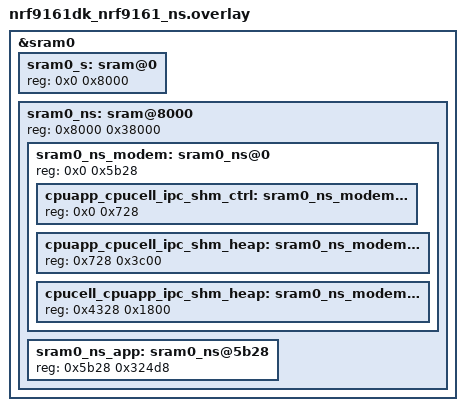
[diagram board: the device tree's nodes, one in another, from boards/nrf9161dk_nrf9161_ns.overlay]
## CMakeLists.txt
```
#
# Copyright (c) 2024 Nordic Semiconductor
#
# SPDX-License-Identifier: LicenseRef-Nordic-5-Clause
#

cmake_minimum_required(VERSION 3.20.0)

find_package(Zephyr REQUIRED HINTS $ENV{ZEPHYR_BASE})
project(hello_dect)

target_sources(app PRIVATE src/main.c)
```

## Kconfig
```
#
# Copyright (c) 2024 Nordic Semiconductor
#
# SPDX-License-Identifier: LicenseRef-Nordic-5-Clause
#

config CARRIER
	int "Carrier to use"
	default 0
	help
	   The availability of the channels and the exact regulation to use them varies in different countries.
	   See ETSI TS 103 636-2 5.4.2 for the calculation.
	   Band index 1 is set when the carrier is within the range of 525 to 551.
	   This is the only range allowed for band index 1 as other carriers will interfere with other radio devices, including LTE devices.

config NETWORK_ID
	int "Network ID"
	range 1 4294967295
	default 91

config MCS
	int "MCS"
	default 1
	help
	   The MCS impacts how much data can fit into each subslot.

config TX_POWER
	int "TX power"
	range 0 13
	default 13
	help
	   Transmission power, max 19 dBm due to hardware limitations.
	   See table 6.2.1-3 of ETSI TS 103 636-4 v1.5.1.

config TX_TRANSMISSIONS
	int "TX transmissions"
	range 0 4294967295
	default 30
	help
	   Transmissions before sample exits, use 0 to transmit forever.

config RX_PERIOD_S
	int "RX period"
	default 5
	help
	   Receive window period.
	   Time is given in seconds.

module = DECT_PHY_HELLO
module-str = DECT NR+ PHY Hello
source "$(ZEPHYR_BASE)/subsys/logging/Kconfig.template.log_config"

menu "Zephyr Kernel"
source "Kconfig.zephyr"
endmenu
```

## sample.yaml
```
sample:
  name: Dect NR+ PHY Hello
tests:
  sample.dect_phy.dect_hello.eu.sysbuild:
    sysbuild: true
    build_only: true
    integration_platforms:
      - nrf9151dk/nrf9151/ns
    platform_allow:
      - nrf9151dk/nrf9151/ns
    extra_args: EXTRA_CONF_FILE="overlay-eu.conf"
    tags:
      - ci_build
      - sysbuild
      - ci_samples_dect
  sample.dect_phy.dect_hello.us.sysbuild:
    sysbuild: true
    build_only: true
    integration_platforms:
      - nrf9151dk/nrf9151/ns
    platform_allow:
      - nrf9151dk/nrf9151/ns
    extra_args: EXTRA_CONF_FILE="overlay-us.conf"
    tags:
      - ci_build
      - sysbuild
      - ci_samples_dect
```

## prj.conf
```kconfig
CONFIG_TFM_PROFILE_TYPE_MINIMAL=y

CONFIG_NRF_MODEM_LIB=y

CONFIG_MODEM_ANTENNA=n

CONFIG_NRF_MODEM_LINK_BINARY_DECT_PHY=y
CONFIG_HWINFO=y

CONFIG_LOG=y
```

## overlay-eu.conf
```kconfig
CONFIG_CARRIER=1677
```

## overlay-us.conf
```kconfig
CONFIG_CARRIER=1711
CONFIG_TX_POWER=10
```

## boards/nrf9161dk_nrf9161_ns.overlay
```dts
/*
 * Copyright (c) 2026 Nordic Semiconductor ASA
 *
 * SPDX-License-Identifier: LicenseRef-Nordic-5-Clause
 */

#include <samples/cellular/nrf91_no_bootloader_partitions.dtsi>

/delete-node/ &sram0_s;
/delete-node/ &sram0_ns;

&sram0 {
	/*
	 * 0x2000_0000  Secure RAM                      (   32 kB)
	 * 0x2000_8000  Non-secure RAM area             (  224 kB)
	 *   0x2000_8000  Modem shared area             ( 23336 B)
	 *     0x2000_8000  control                     (  1832 B)
	 *     0x2000_8728  app -> cell                 (   15 kB)
	 *     0x2000_c328  cell -> app                 (    6 kB)
	 *   0x2000_db28  Application RAM               (206040 B)
	 */
	sram0_s: sram@0 {
		reg = <0x0 0x8000>;
	};

	sram0_ns: sram@8000 {
		reg = <0x8000 0x38000>;
		#address-cells = <1>;
		#size-cells = <1>;
		ranges = <0x0 0x8000 0x38000>;

		/* Must be in first 128 kB of RAM. */
		sram0_ns_modem: sram0_ns@0 {
			/* Modem (shared) memory */
			reg = <0x0 0x5b28>;
			#address-cells = <1>;
			#size-cells = <1>;
			ranges = <0x0 0x0 0x5b28>;

			cpuapp_cpucell_ipc_shm_ctrl: sram0_ns_modem@0 {
				/* Modem IPC control */
				reg = <0x0 0x728>;
			};

			cpuapp_cpucell_ipc_shm_heap: sram0_ns_modem@728 {
				/* Modem IPC transmit */
				reg = <0x728 0x3c00>;
			};

			cpucell_cpuapp_ipc_shm_heap: sram0_ns_modem@4328 {
				/* Modem IPC receive */
				reg = <0x4328 0x1800>;
			};
		};

		sram0_ns_app: sram0_ns@5b28 {
			/* Non-Secure application memory */
			reg = <0x5b28 0x324d8>;
		};
	};
};
```

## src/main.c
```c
/*
 * Copyright (c) 2024 Nordic Semiconductor ASA
 *
 * SPDX-License-Identifier: LicenseRef-Nordic-5-Clause
 */
#include <string.h>
#include <zephyr/kernel.h>
#include <zephyr/logging/log.h>
#include <nrf_modem_dect_phy.h>
#include <modem/nrf_modem_lib.h>
#include <zephyr/drivers/hwinfo.h>

LOG_MODULE_REGISTER(app);

BUILD_ASSERT(CONFIG_CARRIER, "Carrier must be configured according to local regulations");

#define DATA_LEN_MAX 32

static bool exit;
static uint16_t device_id;
static uint64_t modem_time;

/* Header type 1, due to endianness the order is different than in the specification. */
struct phy_ctrl_field_common {
	uint32_t packet_length : 4;
	uint32_t packet_length_type : 1;
	uint32_t header_format : 3;
	uint32_t short_network_id : 8;
	uint32_t transmitter_id_hi : 8;
	uint32_t transmitter_id_lo : 8;
	uint32_t df_mcs : 3;
	uint32_t reserved : 1;
	uint32_t transmit_power : 4;
	uint32_t pad : 24;
};

/* Semaphore to synchronize modem calls. */
K_SEM_DEFINE(operation_sem, 0, 1);

K_SEM_DEFINE(deinit_sem, 0, 1);

/* Callback after init operation. */
static void on_init(const struct nrf_modem_dect_phy_init_event *evt)
{
	if (evt->err) {
		LOG_ERR("Init failed, err %d", evt->err);
		exit = true;
		return;
	}

	k_sem_give(&operation_sem);
}

/* Callback after deinit operation. */
static void on_deinit(const struct nrf_modem_dect_phy_deinit_event *evt)
{
	if (evt->err) {
		LOG_ERR("Deinit failed, err %d", evt->err);
		return;
	}

	k_sem_give(&deinit_sem);
}

static void on_activate(const struct nrf_modem_dect_phy_activate_event *evt)
{
	if (evt->err) {
		LOG_ERR("Activate failed, err %d", evt->err);
		exit = true;
		return;
	}

	k_sem_give(&operation_sem);
}

static void on_deactivate(const struct nrf_modem_dect_phy_deactivate_event *evt)
{

	if (evt->err) {
		LOG_ERR("Deactivate failed, err %d", evt->err);
		return;
	}

	k_sem_give(&deinit_sem);
}

static void on_configure(const struct nrf_modem_dect_phy_configure_event *evt)
{
	if (evt->err) {
		LOG_ERR("Configure failed, err %d", evt->err);
		return;
	}

	k_sem_give(&operation_sem);
}

/* Callback after link configuration operation. */
static void on_link_config(const struct nrf_modem_dect_phy_link_config_event *evt)
{
	LOG_DBG("link_config cb time %"PRIu64" status %d", modem_time, evt->err);
}

static void on_radio_config(const struct nrf_modem_dect_phy_radio_config_event *evt)
{
	if (evt->err) {
		LOG_ERR("Radio config failed, err %d", evt->err);
		return;
	}

	k_sem_give(&operation_sem);
}

/* Callback after capability get operation. */
static void on_capability_get(const struct nrf_modem_dect_phy_capability_get_event *evt)
{
	LOG_DBG("capability_get cb time %"PRIu64" status %d", modem_time, evt->err);
}

static void on_bands_get(const struct nrf_modem_dect_phy_band_get_event *evt)
{
	LOG_DBG("bands_get cb status %d", evt->err);
}

static void on_latency_info_get(const struct nrf_modem_dect_phy_latency_info_event *evt)
{
	LOG_DBG("latency_info_get cb status %d", evt->err);
}

/* Callback after time query operation. */
static void on_time_get(const struct nrf_modem_dect_phy_time_get_event *evt)
{
	LOG_DBG("time_get cb time %"PRIu64" status %d", modem_time, evt->err);
}

static void on_cancel(const struct nrf_modem_dect_phy_cancel_event *evt)
{
	LOG_DBG("on_cancel cb status %d", evt->err);
	k_sem_give(&operation_sem);
}

/* Operation complete notification. */
static void on_op_complete(const struct nrf_modem_dect_phy_op_complete_event *evt)
{
	LOG_DBG("op_complete cb time %"PRIu64" status %d", modem_time, evt->err);
	k_sem_give(&operation_sem);
}

/* Physical Control Channel reception notification. */
static void on_pcc(const struct nrf_modem_dect_phy_pcc_event *evt)
{
	LOG_INF("Received header from device ID %d",
		evt->hdr.hdr_type_1.transmitter_id_hi << 8 | evt->hdr.hdr_type_1.transmitter_id_lo);
}

/* Physical Control Channel CRC error notification. */
static void on_pcc_crc_err(const struct nrf_modem_dect_phy_pcc_crc_failure_event *evt)
{
	LOG_DBG("pcc_crc_err cb time %"PRIu64"", modem_time);
}

/* Physical Data Channel reception notification. */
static void on_pdc(const struct nrf_modem_dect_phy_pdc_event *evt)
{
	/* Received RSSI value is in fixed precision format Q14.1 */
	LOG_INF("Received data (RSSI: %d.%d): %s",
		(evt->rssi_2 / 2), (evt->rssi_2 & 0b1) * 5, (char *)evt->data);
}

/* Physical Data Channel CRC error notification. */
static void on_pdc_crc_err(const struct nrf_modem_dect_phy_pdc_crc_failure_event *evt)
{
	LOG_DBG("pdc_crc_err cb time %"PRIu64"", modem_time);
}

/* RSSI measurement result notification. */
static void on_rssi(const struct nrf_modem_dect_phy_rssi_event *evt)
{
	LOG_DBG("rssi cb time %"PRIu64" carrier %d", modem_time, evt->carrier);
}

static void on_stf_cover_seq_control(const struct nrf_modem_dect_phy_stf_control_event *evt)
{
	LOG_WRN("Unexpectedly in %s\n", (__func__));
}

static void on_test_rf_tx_cw_ctrl(const struct nrf_modem_dect_phy_test_rf_tx_cw_control_event *evt)
{
	LOG_WRN("Unexpectedly in %s\n", (__func__));
}

static void on_reject(const struct nrf_modem_dect_phy_reject_event *evt)
{
	LOG_WRN("Unexpectedly in %s\n", (__func__));
}

static void dect_phy_event_handler(const struct nrf_modem_dect_phy_event *evt)
{
	modem_time = evt->time;

	switch (evt->id) {
	case NRF_MODEM_DECT_PHY_EVT_INIT:
		on_init(&evt->init);
		break;
	case NRF_MODEM_DECT_PHY_EVT_DEINIT:
		on_deinit(&evt->deinit);
		break;
	case NRF_MODEM_DECT_PHY_EVT_ACTIVATE:
		on_activate(&evt->activate);
		break;
	case NRF_MODEM_DECT_PHY_EVT_DEACTIVATE:
		on_deactivate(&evt->deactivate);
		break;
	case NRF_MODEM_DECT_PHY_EVT_CONFIGURE:
		on_configure(&evt->configure);
		break;
	case NRF_MODEM_DECT_PHY_EVT_RADIO_CONFIG:
		on_radio_config(&evt->radio_config);
		break;
	case NRF_MODEM_DECT_PHY_EVT_COMPLETED:
		on_op_complete(&evt->op_complete);
		break;
	case NRF_MODEM_DECT_PHY_EVT_CANCELED:
		on_cancel(&evt->cancel);
		break;
	case NRF_MODEM_DECT_PHY_EVT_RSSI:
		on_rssi(&evt->rssi);
		break;
	case NRF_MODEM_DECT_PHY_EVT_PCC:
		on_pcc(&evt->pcc);
		break;
	case NRF_MODEM_DECT_PHY_EVT_PCC_ERROR:
		on_pcc_crc_err(&evt->pcc_crc_err);
		break;
	case NRF_MODEM_DECT_PHY_EVT_PDC:
		on_pdc(&evt->pdc);
		break;
	case NRF_MODEM_DECT_PHY_EVT_PDC_ERROR:
		on_pdc_crc_err(&evt->pdc_crc_err);
		break;
	case NRF_MODEM_DECT_PHY_EVT_TIME:
		on_time_get(&evt->time_get);
		break;
	case NRF_MODEM_DECT_PHY_EVT_CAPABILITY:
		on_capability_get(&evt->capability_get);
		break;
	case NRF_MODEM_DECT_PHY_EVT_BANDS:
		on_bands_get(&evt->band_get);
		break;
	case NRF_MODEM_DECT_PHY_EVT_LATENCY:
		on_latency_info_get(&evt->latency_get);
		break;
	case NRF_MODEM_DECT_PHY_EVT_LINK_CONFIG:
		on_link_config(&evt->link_config);
		break;
	case NRF_MODEM_DECT_PHY_EVT_STF_CONFIG:
		on_stf_cover_seq_control(&evt->stf_cover_seq_control);
		break;
	case NRF_MODEM_DECT_PHY_EVT_TEST_RF_TX_CW_CONTROL_CONFIG:
		on_test_rf_tx_cw_ctrl(&evt->test_rf_tx_cw_control);
		break;
	case NRF_MODEM_DECT_PHY_EVT_REJECT:
		on_reject(&evt->reject);
		break;
	}
}

/* Dect PHY config parameters. */
static struct nrf_modem_dect_phy_config_params dect_phy_config_params = {
	.band_group_index = ((CONFIG_CARRIER >= 525 && CONFIG_CARRIER <= 551)) ? 1 : 0,
	.harq_rx_process_count = 4,
	.harq_rx_expiry_time_us = 5000000,
};

/* Send operation. */
static int transmit(uint32_t handle, void *data, size_t data_len)
{
	int err;

	struct phy_ctrl_field_common header = {
		.header_format = 0x0,
		.packet_length_type = 0x0,
		.packet_length = 0x01,
		.short_network_id = (CONFIG_NETWORK_ID & 0xff),
		.transmitter_id_hi = (device_id >> 8),
		.transmitter_id_lo = (device_id & 0xff),
		.transmit_power = CONFIG_TX_POWER,
		.reserved = 0,
		.df_mcs = CONFIG_MCS,
	};

	struct nrf_modem_dect_phy_tx_params tx_op_params = {
		.start_time = 0,
		.handle = handle,
		.network_id = CONFIG_NETWORK_ID,
		.phy_type = 0,
		.lbt_rssi_threshold_max = 0,
		.carrier = CONFIG_CARRIER,
		.lbt_period = NRF_MODEM_DECT_LBT_PERIOD_MAX,
		.phy_header = (union nrf_modem_dect_phy_hdr *)&header,
		.data = data,
		.data_size = data_len,
	};

	err = nrf_modem_dect_phy_tx(&tx_op_params);
	if (err != 0) {
		return err;
	}

	return 0;
}

/* Receive operation. */
static int receive(uint32_t handle)
{
	int err;

	struct nrf_modem_dect_phy_rx_params rx_op_params = {
		.start_time = 0,
		.handle = handle,
		.network_id = CONFIG_NETWORK_ID,
		.mode = NRF_MODEM_DECT_PHY_RX_MODE_CONTINUOUS,
		.rssi_interval = NRF_MODEM_DECT_PHY_RSSI_INTERVAL_OFF,
		.link_id = NRF_MODEM_DECT_PHY_LINK_UNSPECIFIED,
		.rssi_level = -60,
		.carrier = CONFIG_CARRIER,
		.duration = CONFIG_RX_PERIOD_S * MSEC_PER_SEC *
			    NRF_MODEM_DECT_MODEM_TIME_TICK_RATE_KHZ,
		.filter.short_network_id = CONFIG_NETWORK_ID & 0xff,
		.filter.is_short_network_id_used = 1,
		/* listen for everything (broadcast mode used) */
		.filter.receiver_identity = 0,
	};

	err = nrf_modem_dect_phy_rx(&rx_op_params);
	if (err != 0) {
		return err;
	}

	return 0;
}

int main(void)
{
	int err;
	uint32_t tx_handle = 0;
	uint32_t rx_handle = 1;
	uint32_t tx_counter_value = 0;
	uint8_t tx_buf[DATA_LEN_MAX];
	size_t tx_len;

	LOG_INF("Dect NR+ PHY Hello sample started");

	err = nrf_modem_lib_init();
	if (err) {
		LOG_ERR("modem init failed, err %d", err);
		return err;
	}

	err = nrf_modem_dect_phy_event_handler_set(dect_phy_event_handler);
	if (err) {
		LOG_ERR("nrf_modem_dect_phy_event_handler_set failed, err %d", err);
		return err;
	}

	err = nrf_modem_dect_phy_init();
	if (err) {
		LOG_ERR("nrf_modem_dect_phy_init failed, err %d", err);
		return err;
	}

	k_sem_take(&operation_sem, K_FOREVER);
	if (exit) {
		return -EIO;
	}

	err = nrf_modem_dect_phy_configure(&dect_phy_config_params);
	if (err) {
		LOG_ERR("nrf_modem_dect_phy_configure failed, err %d", err);
		return err;
	}

	k_sem_take(&operation_sem, K_FOREVER);
	if (exit) {
		return -EIO;
	}

	err = nrf_modem_dect_phy_activate(NRF_MODEM_DECT_PHY_RADIO_MODE_LOW_LATENCY);
	if (err) {
		LOG_ERR("nrf_modem_dect_phy_activate failed, err %d", err);
		return err;
	}

	k_sem_take(&operation_sem, K_FOREVER);
	if (exit) {
		return -EIO;
	}

	hwinfo_get_device_id((void *)&device_id, sizeof(device_id));

	LOG_INF("Dect NR+ PHY initialized, device ID: %d", device_id);

	err = nrf_modem_dect_phy_capability_get();
	if (err) {
		LOG_ERR("nrf_modem_dect_phy_capability_get failed, err %d", err);
	}

	while (1) {
		/** Transmitting message */
		LOG_INF("Transmitting %d", tx_counter_value);
		tx_len = sprintf(tx_buf, "Hello DECT! %d", tx_counter_value) + 1; /* Include \0 */

		err = transmit(tx_handle, tx_buf, tx_len);
		if (err) {
			LOG_ERR("Transmisstion failed, err %d", err);
			return err;
		}

		tx_counter_value++;

		/* Wait for TX operation to complete. */
		k_sem_take(&operation_sem, K_FOREVER);

		if ((tx_counter_value >= CONFIG_TX_TRANSMISSIONS) && CONFIG_TX_TRANSMISSIONS) {
			LOG_INF("Reached maximum number of transmissions (%d)",
				CONFIG_TX_TRANSMISSIONS);
			break;
		}

		/** Receiving messages for CONFIG_RX_PERIOD_S seconds. */
		err = receive(rx_handle);
		if (err) {
			LOG_ERR("Reception failed, err %d", err);
			return err;
		}

		/* Wait for RX operation to complete. */
		k_sem_take(&operation_sem, K_FOREVER);
	}

	LOG_INF("Shutting down");

	err = nrf_modem_dect_phy_deactivate();
	if (err) {
		LOG_ERR("nrf_modem_dect_phy_deactivate failed, err %d", err);
		return err;
	}

	k_sem_take(&deinit_sem, K_FOREVER);

	err = nrf_modem_dect_phy_deinit();
	if (err) {
		LOG_ERR("nrf_modem_dect_phy_deinit() failed, err %d", err);
		return err;
	}

	k_sem_take(&deinit_sem, K_FOREVER);

	err = nrf_modem_lib_shutdown();
	if (err) {
		LOG_ERR("nrf_modem_lib_shutdown() failed, err %d", err);
		return err;
	}

	LOG_INF("Bye!");

	return 0;
}
```
